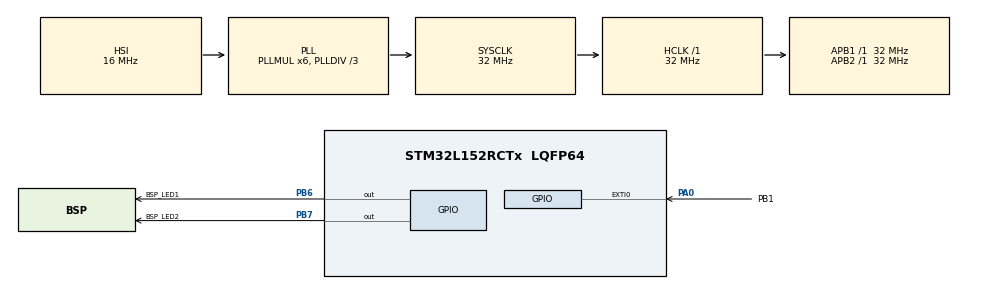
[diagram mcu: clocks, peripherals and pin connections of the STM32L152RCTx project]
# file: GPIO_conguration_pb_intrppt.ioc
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Mcu.Family=STM32L1
Mcu.Name=STM32L152RCTx
Mcu.Package=LQFP64
NVIC.EXTI0_IRQn=true\:0\:0\:false\:false\:true\:true\:true\:true
NVIC.FLASH_IRQn=true\:0\:0\:false\:false\:true\:true\:true\:true
NVIC.PriorityGroup=NVIC_PRIORITYGROUP_0
NVIC.RCC_IRQn=true\:0\:0\:false\:false\:true\:true\:false\:true
PA0-WKUP1.GPIO_Label=PB1
PA0-WKUP1.GPIO_ModeDefaultEXTI=GPIO_MODE_IT_FALLING
PA0-WKUP1.Signal=GPXTI0
PB6.GPIO_Label=BSP_LED1
PB6.Signal=GPIO_Output
PB7.GPIO_Label=BSP_LED2
PB7.Signal=GPIO_Output
ProjectManager.HeapSize=0x200
ProjectManager.StackSize=0x400
ProjectManager.TargetToolchain=STM32CubeIDE
RCC.48MHZClocksFreq_Value=48000000
RCC.AHBFreq_Value=32000000
RCC.APB1Freq_Value=32000000
RCC.APB1TimFreq_Value=32000000
RCC.APB2Freq_Value=32000000
RCC.APB2TimFreq_Value=32000000
RCC.HCLKFreq_Value=32000000
RCC.HSE_VALUE=8000000
RCC.HSI_VALUE=16000000
RCC.LSE_VALUE=32768
RCC.MSI_VALUE=2097000
RCC.PLLDIV=RCC_PLL_DIV3
RCC.PLLMUL=RCC_PLL_MUL6
RCC.RTCClockSelectionVirtual=RCC_RTCCLKSOURCE_LSE
RCC.SYSCLKFreq_VALUE=32000000
RCC.SYSCLKSource=RCC_SYSCLKSOURCE_PLLCLK
RCC.USBOutput=48000000
RCC.VCOOutputFreq_Value=96000000
board=STM32L152C-DISCO

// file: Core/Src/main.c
/* USER CODE BEGIN Header */
/**
 ******************************************************************************
 * @file           : main.c
 * @brief          : Main program body
 ******************************************************************************
 * @attention
 *
 * Copyright (c) 2023 STMicroelectronics.
 * All rights reserved.
 *
 * This software is licensed under terms that can be found in the LICENSE file
 * in the root directory of this software component.
 * If no LICENSE file comes with this software, it is provided AS-IS.
 *
 ******************************************************************************
 */
/* USER CODE END Header */
#include "main.h"
#include "gpio.h"

/* USER CODE BEGIN Includes */
#include"stdbool.h"
/* USER CODE END Includes */

/* USER CODE BEGIN PV */
static volatile bool flag = 0;

/* USER CODE END PV */

void SystemClock_Config(void);

int main(void) {

	/* MCU Configuration--------------------------------------------------------*/

	/* Reset of all peripherals, Initializes the Flash interface and the Systick. */
	HAL_Init();

	/* Configure the system clock */
	SystemClock_Config();

	/* Initialize all configured peripherals */
	MX_GPIO_Init();

	/* Infinite loop */
	while (1) {

		/* USER CODE BEGIN 3 */
		if (flag == 1)     // in this inruppt is tringer flag is 1 so
		{					// so led2 is toggle
			HAL_GPIO_TogglePin(BSP_LED2_GPIO_Port, BSP_LED2_Pin);
			HAL_Delay(50);
		}
				flag = 0;	// flag is 0 so next
				HAL_GPIO_TogglePin(BSP_LED1_GPIO_Port, BSP_LED1_Pin);
				HAL_Delay(50);

	}
	/* USER CODE END 3 */
}

void SystemClock_Config(void) {
	RCC_OscInitTypeDef RCC_OscInitStruct = { 0 };
	RCC_ClkInitTypeDef RCC_ClkInitStruct = { 0 };

	/** Configure the main internal regulator output voltage
	 */
	__HAL_PWR_VOLTAGESCALING_CONFIG(PWR_REGULATOR_VOLTAGE_SCALE1);

	/** Initializes the RCC Oscillators according to the specified parameters
	 * in the RCC_OscInitTypeDef structure.
	 */
	RCC_OscInitStruct.OscillatorType = RCC_OSCILLATORTYPE_HSI;
	RCC_OscInitStruct.HSIState = RCC_HSI_ON;
	RCC_OscInitStruct.HSICalibrationValue = RCC_HSICALIBRATION_DEFAULT;
	RCC_OscInitStruct.PLL.PLLState = RCC_PLL_ON;
	RCC_OscInitStruct.PLL.PLLSource = RCC_PLLSOURCE_HSI;
	RCC_OscInitStruct.PLL.PLLMUL = RCC_PLL_MUL6;
	RCC_OscInitStruct.PLL.PLLDIV = RCC_PLL_DIV3;
	if (HAL_RCC_OscConfig(&RCC_OscInitStruct) != HAL_OK) {
		Error_Handler();
	}

	/** Initializes the CPU, AHB and APB buses clocks
	 */
	RCC_ClkInitStruct.ClockType = RCC_CLOCKTYPE_HCLK | RCC_CLOCKTYPE_SYSCLK
			| RCC_CLOCKTYPE_PCLK1 | RCC_CLOCKTYPE_PCLK2;
	RCC_ClkInitStruct.SYSCLKSource = RCC_SYSCLKSOURCE_PLLCLK;
	RCC_ClkInitStruct.AHBCLKDivider = RCC_SYSCLK_DIV1;
	RCC_ClkInitStruct.APB1CLKDivider = RCC_HCLK_DIV1;
	RCC_ClkInitStruct.APB2CLKDivider = RCC_HCLK_DIV1;

	if (HAL_RCC_ClockConfig(&RCC_ClkInitStruct, FLASH_LATENCY_1) != HAL_OK) {
		Error_Handler();
	}
}

/* USER CODE BEGIN 4 */
void HAL_GPIO_EXTI_Callback(uint16_t GPIO_Pin) {
	flag = 1;
}

/* USER CODE END 4 */

void Error_Handler(void) {
	__disable_irq();
	while (1) {
	}
}
